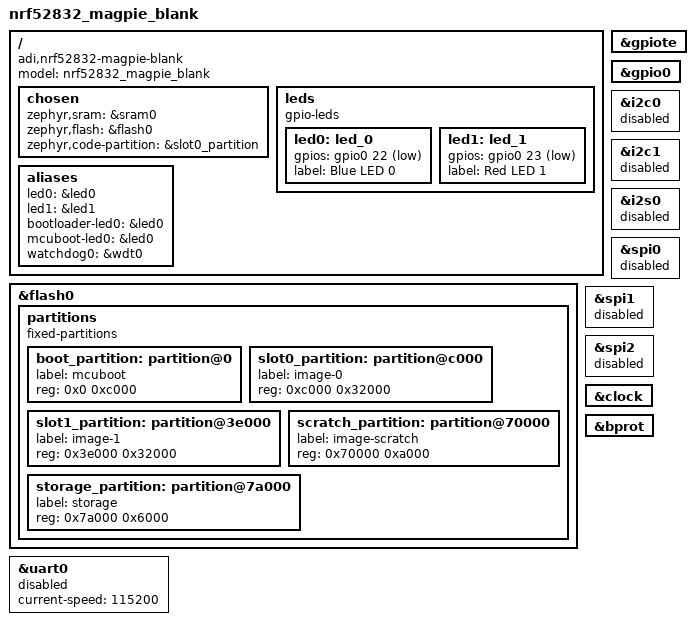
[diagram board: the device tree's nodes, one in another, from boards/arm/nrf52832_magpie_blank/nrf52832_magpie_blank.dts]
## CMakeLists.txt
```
# SPDX-License-Identifier: Apache-2.0

cmake_minimum_required(VERSION 3.20.0)
find_package(Zephyr REQUIRED HINTS $ENV{ZEPHYR_BASE})
project(blinky_magpie)

target_sources(app PRIVATE src/main.c)
```

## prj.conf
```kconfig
CONFIG_GPIO=y

CONFIG_CORTEX_M_DEBUG_MONITOR_HOOK=y
CONFIG_DEBUG_THREAD_INFO=y
CONFIG_SEGGER_DEBUGMON=y
CONFIG_DEBUG_OPTIMIZATIONS=y
CONFIG_KERNEL_BIN_NAME="nrf52832_magpie_blank"

CONFIG_CLOCK_CONTROL_NRF_K32SRC_EXT_FULL_SWING=y
CONFIG_CLOCK_CONTROL_NRF_K32SRC_20PPM=y
CONFIG_CLOCK_CONTROL_FIXED_RATE_CLOCK=y
```

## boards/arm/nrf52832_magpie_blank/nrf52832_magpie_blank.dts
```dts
// Copyright (c) 2024 Nordic Semiconductor ASA
// SPDX-License-Identifier: Apache-2.0

/dts-v1/;
#include <nordic/nrf52832_ciaa.dtsi>

/ {
	model = "nrf52832_magpie_blank";
	compatible = "adi,nrf52832-magpie-blank";

	chosen {
		zephyr,sram = &sram0;
		zephyr,flash = &flash0;
		zephyr,code-partition = &slot0_partition;
	};

	leds {
		compatible = "gpio-leds";
		led0: led_0 {
			gpios = <&gpio0 22 GPIO_ACTIVE_LOW>;
			label = "Blue LED 0";
		};
		led1: led_1 {
			gpios = <&gpio0 23 GPIO_ACTIVE_LOW>;
			label = "Red LED 1";
		};		
	};

	aliases {
		led0 = &led0;
		led1 = &led1;
		bootloader-led0 = &led0;
		mcuboot-led0 = &led0;
		watchdog0 = &wdt0;
	};
};

&gpiote {
	status = "okay";
};

&gpio0 {
	status = "okay";
};

&flash0 {
	partitions {
		compatible = "fixed-partitions";
		#address-cells = <1>;
		#size-cells = <1>;

		boot_partition: partition@0 {
			label = "mcuboot";
			reg = <0x0 0xc000>;
		};
		slot0_partition: partition@c000 {
			label = "image-0";
			reg = <0xc000 0x32000>;
		};
		slot1_partition: partition@3e000 {
			label = "image-1";
			reg = <0x3e000 0x32000>;
		};
		scratch_partition: partition@70000 {
			label = "image-scratch";
			reg = <0x70000 0xa000>;
		};
		storage_partition: partition@7a000 {
			label = "storage";
			reg = <0x7a000 0x6000>;
		};
	};
};





&i2c0 {
	status = "disabled";
};

&i2c1 {
	status = "disabled";
};

&i2s0 {
	status = "disabled";
};

&spi0 {
	status = "disabled";
};

&spi1 {
	status = "disabled";
};

&spi2 {
	status = "disabled";
};

&uart0 {
	status = "disabled";
	current-speed = <115200>;
};

&clock {
	status = "okay";
};

&bprot {
	status = "okay";
};
```

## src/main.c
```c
/*
 * Copyright (c) 2016 Intel Corporation
 *
 * SPDX-License-Identifier: Apache-2.0
 */

#include <zephyr/kernel.h>
#include <zephyr/drivers/gpio.h>

/* 1000 msec = 1 sec */
#define SLEEP_TIME_MS   2000

/* The devicetree node identifier for the "led0" alias. */
#define LED0_NODE DT_ALIAS(led0)
#define LED1_NODE DT_ALIAS(led1)

/*
 * A build error on this line means your board is unsupported.
 * See the sample documentation for information on how to fix this.
 */
static const struct gpio_dt_spec led_blue = GPIO_DT_SPEC_GET(LED0_NODE, gpios);
static const struct gpio_dt_spec led_red = GPIO_DT_SPEC_GET(LED1_NODE, gpios);

int main(void)
{
	int ret;

	if (!gpio_is_ready_dt(&led_blue)) {
		return 0;
	}

	if (!gpio_is_ready_dt(&led_red)) {
		return 0;
	}

	ret = gpio_pin_configure_dt(&led_blue, GPIO_OUTPUT_ACTIVE);
	if (ret < 0) {
		return 0;
	}

	ret = gpio_pin_configure_dt(&led_red, GPIO_OUTPUT_ACTIVE);
	if (ret < 0) {
		return 0;
	}

	ret = gpio_pin_toggle_dt(&led_red);		
	if (ret < 0) {
		return 0;
	}

	while (1) {
		ret = gpio_pin_toggle_dt(&led_blue);		
		if (ret < 0) {
			return 0;
		}
		ret = gpio_pin_toggle_dt(&led_red);		
		if (ret < 0) {
			return 0;
		}

		k_msleep(SLEEP_TIME_MS);
	}
	return 0;
}
```
